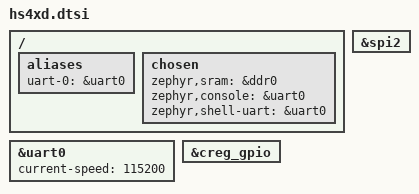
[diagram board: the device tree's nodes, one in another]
/*
 * Copyright (c) 2019, Synopsys, Inc. All rights reserved.
 *
 * SPDX-License-Identifier: Apache-2.0
 */

/dts-v1/;

#include <synopsys/arc_hsdk.dtsi>

/ {

	aliases {
		uart-0 = &uart0;
	};

	chosen {
		zephyr,sram = &ddr0;
		zephyr,console = &uart0;
		zephyr,shell-uart = &uart0;
	};

};

arduino_spi: &spi2 {};

&uart0 {
	status = "okay";
	current-speed = <115200>;
};

&creg_gpio {
	status = "okay";
};
